# TMS320F28M35x_M3 register map
Vendor: Texas Instruments; Series: C2000 Concerto F28M35x; File version: 0.2.0-generated
CPU: CM3 r2p1, little endian, no MPU, no FPU, 3 interrupt priority bits
Registers are 32-bit, read-write, reset 0x0 unless marked. A register's access mark holds for its fields unless they carry their own. Offsets are from the block's base; [hi:lo] are bit positions; {n}, {i} and the like mark numbered series.

## USB0 — Univeral Serial Bus register offsets
Base 0x40050000
0x00 USB_FADDR 64-bit — USB Device Functional Address
  [12:6] USB_FADDR — Function Address
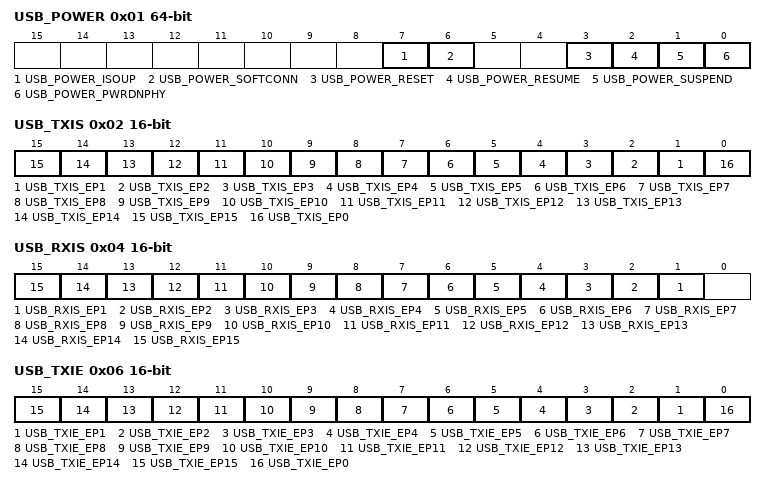
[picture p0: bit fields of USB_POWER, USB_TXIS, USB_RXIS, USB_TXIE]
0x01 USB_POWER 64-bit
  [7] USB_POWER_ISOUP — Isochronous Update
  [6] USB_POWER_SOFTCONN — Soft Connect/Disconnect
  [3] USB_POWER_RESET — RESET Signaling
  [2] USB_POWER_RESUME — RESUME Signaling
  [1] USB_POWER_SUSPEND — SUSPEND Mode
  [0] USB_POWER_PWRDNPHY — Power Down PHY
0x02 USB_TXIS 16-bit — USB Transmit Interrupt Status
  [n] USB_TXIS_EP{n} (n=1..15) — TX Endpoint {n} Interrupt
  [0] USB_TXIS_EP0 — TX and RX Endpoint 0 Interrupt
0x04 USB_RXIS 16-bit — USB Receive Interrupt Status
  [n] USB_RXIS_EP{n} (n=1..15) — RX Endpoint {n} Interrupt
0x06 USB_TXIE 16-bit — USB Transmit Interrupt Enable
  [n] USB_TXIE_EP{n} (n=1..15) — TX Endpoint {n} Interrupt Enable
  [0] USB_TXIE_EP0 — TX and RX Endpoint 0 Interrupt Enable
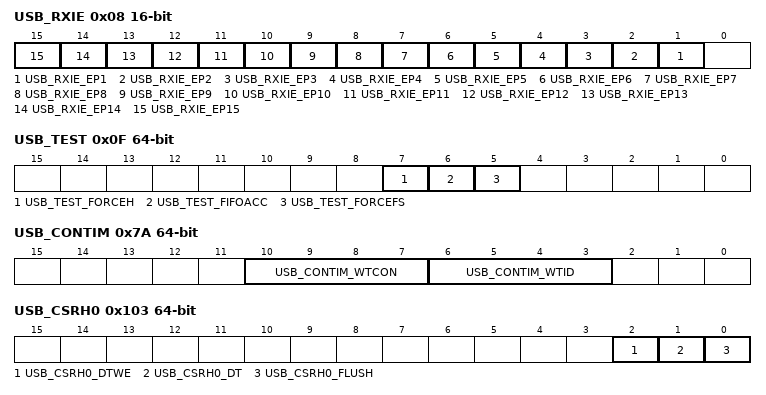
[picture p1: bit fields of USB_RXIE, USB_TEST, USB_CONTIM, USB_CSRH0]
0x08 USB_RXIE 16-bit — USB Receive Interrupt Enable
  [n] USB_RXIE_EP{n} (n=1..15) — RX Endpoint {n} Interrupt Enable
0x0A USB_IS 64-bit — USB General Interrupt Status
  [7] USB_IS_VBUSERR — VBUS Error
  [6] USB_IS_SESREQ — SESSION REQUEST
  [5] USB_IS_DISCON — Session Disconnect
  [4] USB_IS_CONN — Session Connect
  [3] USB_IS_SOF — Start of Frame
  [2] USB_IS_BABBLE — Babble Detected
  [2] USB_IS_RESET — RESET Signaling Detected
  [1] USB_IS_RESUME — RESUME Signaling Detected
  [0] USB_IS_SUSPEND — SUSPEND Signaling Detected
0x0B USB_IE 64-bit — USB Interrupt Enable
  [7] USB_IE_VBUSERR — Enable VBUS Error Interrupt
  [6] USB_IE_SESREQ — Enable Session Request
  [5] USB_IE_DISCON — Enable Disconnect Interrupt
  [4] USB_IE_CONN — Enable Connect Interrupt
  [3] USB_IE_SOF — Enable Start-of-Frame Interrupt
  [2] USB_IE_BABBLE — Enable Babble Interrupt
  [2] USB_IE_RESET — Enable RESET Interrupt
  [1] USB_IE_RESUME — Enable RESUME Interrupt
  [0] USB_IE_SUSPND — Enable SUSPEND Interrupt
0x0C USB_FRAME 16-bit — USB Frame Value
  [15:10] USB_FRAME — Frame Number
0x0E USB_EPIDX 64-bit — USB Endpoint Index
  [6:3] USB_EPIDX_EPIDX — Endpoint Index
0x0F USB_TEST 64-bit — USB Test Mode
  [7] USB_TEST_FORCEH — Force Host Mode
  [6] USB_TEST_FIFOACC — FIFO Access
  [5] USB_TEST_FORCEFS — Force Full-Speed Mode
{0x20+4i} USB_FIFO{i} (i=0..15) — USB FIFO Endpoint {i}
  [31] USB_FIFO{i}_EPDATA — Endpoint Data
0x60 USB_DEVCTL 64-bit — USB Device Control
  [7] USB_DEVCTL_DEV — Device Mode
  [6] USB_DEVCTL_FSDEV — Full-Speed Device Detected
  [5] USB_DEVCTL_LSDEV — Low-Speed Device Detected
  [5:4] USB_DEVCTL_VBUS — VBUS Level
    0=USB_DEVCTL_VBUS_NONE (Below SessionEnd); 8=USB_DEVCTL_VBUS_SEND (Above SessionEnd, below AValid); 16=USB_DEVCTL_VBUS_AVALID (Above AValid, below VBUSValid); 24=USB_DEVCTL_VBUS_VALID (Above VBUSValid)
  [2] USB_DEVCTL_HOST — Host Mode
  [1] USB_DEVCTL_HOSTREQ — Host Request
  [0] USB_DEVCTL_SESSION — Session Start/End
0x62 USB_TXFIFOSZ 64-bit — USB Transmit Dynamic FIFO Sizing
  [4] USB_TXFIFOSZ_DPB — Double Packet Buffer Support
  [6:3] USB_TXFIFOSZ_SIZE — Max Packet Size
    0=8; 1=16; 2=32; 3=64; 4=128; 5=256; 6=512; 7=1024; 8=2048
0x63 USB_RXFIFOSZ 64-bit — USB Receive Dynamic FIFO Sizing
  [4] USB_RXFIFOSZ_DPB — Double Packet Buffer Support
  [6:3] USB_RXFIFOSZ_SIZE — Max Packet Size
    0=8; 1=16; 2=32; 3=64; 4=128; 5=256; 6=512; 7=1024; 8=2048
0x64 USB_TXFIFOADD 16-bit — USB Transmit FIFO Start Address
  [15:8] USB_TXFIFOADD_ADDR — Transmit/Receive Start Address
0x66 USB_RXFIFOADD 16-bit — USB Receive FIFO Start Address
  [15:8] USB_RXFIFOADD_ADDR — Transmit/Receive Start Address
0x7A USB_CONTIM 64-bit — USB Connect Timing
  [10:7] USB_CONTIM_WTCON — Connect Wait
  [6:3] USB_CONTIM_WTID — Wait ID
0x7B USB_VPLEN 64-bit — USB OTG VBUS Pulse Timing
  [14:7] USB_VPLEN_VPLEN — VBUS Pulse Length
0x7D USB_FSEOF 64-bit — USB Full-Speed Last Transaction to End of Frame Timing
  [14:7] USB_FSEOF_FSEOFG — Full-Speed End-of-Frame Gap
0x7E USB_LSEOF 64-bit — USB Low-Speed Last Transaction to End of Frame Timing
  [14:7] USB_LSEOF_LSEOFG — Low-Speed End-of-Frame Gap
{0x80+8i} USB_TXFUNCADDR{i} 64-bit (i=0..15) — USB Transmit Functional Address Endpoint {i}
  [12:6] USB_TXFUNCADDR{i}_ADDR — Device Address
{0x82+8i} USB_TXHUBADDR{i} 64-bit (i=0..15) — USB Transmit Hub Address Endpoint {i}
  [7] USB_TXHUBADDR{i}_MULTTRAN — Multiple Translators
  [12:6] USB_TXHUBADDR{i}_ADDR — Hub Address
{0x83+8i} USB_TXHUBPORT{i} 64-bit (i=0..15) — USB Transmit Hub Port Endpoint {i}
  [12:6] USB_TXHUBPORT{i}_PORT — Hub Port
{0x84+8i} USB_RXFUNCADDR{i} 64-bit (i=1..15) — USB Receive Functional Address Endpoint {i}
  [12:6] USB_RXFUNCADDR{i}_ADDR — Device Address
{0x86+8i} USB_RXHUBADDR{i} 64-bit (i=1..15) — USB Receive Hub Address Endpoint {i}
  [7] USB_RXHUBADDR{i}_MULTTRAN — Multiple Translators
  [12:6] USB_RXHUBADDR{i}_ADDR — Hub Address
{0x87+8i} USB_RXHUBPORT{i} 64-bit (i=1..15) — USB Receive Hub Port Endpoint {i}
  [12:6] USB_RXHUBPORT{i}_PORT — Hub Port
0x102 USB_CSRL0 64-bit — USB Control and Status Endpoint 0 Low
  [7] USB_CSRL0_NAKTO — NAK Timeout
  [7] USB_CSRL0_SETENDC — Setup End Clear
  [6] USB_CSRL0_RXRDYC — RXRDY Clear
  [6] USB_CSRL0_STATUS — STATUS Packet
  [5] USB_CSRL0_REQPKT — Request Packet
  [5] USB_CSRL0_STALL — Send Stall
  [4] USB_CSRL0_ERROR — Error
  [4] USB_CSRL0_SETEND — Setup End
  [3] USB_CSRL0_DATAEND — Data End
  [3] USB_CSRL0_SETUP — Setup Packet
  [2] USB_CSRL0_STALLED — Endpoint Stalled
  [1] USB_CSRL0_TXRDY — Transmit Packet Ready
  [0] USB_CSRL0_RXRDY — Receive Packet Ready
0x103 USB_CSRH0 64-bit — USB Control and Status Endpoint 0 High
  [2] USB_CSRH0_DTWE — Data Toggle Write Enable
  [1] USB_CSRH0_DT — Data Toggle
  [0] USB_CSRH0_FLUSH — Flush FIFO
0x108 USB_COUNT0 64-bit — USB Receive Byte Count Endpoint 0
  [12:6] USB_COUNT0_COUNT — FIFO Count
0x10A USB_TYPE0 64-bit — USB Type Endpoint 0
  [8:7] USB_TYPE0_SPEED — Operating Speed
    128=USB_TYPE0_SPEED_FULL (Full); 192=USB_TYPE0_SPEED_LOW (Low)
0x10B USB_NAKLMT 64-bit — USB NAK Limit
  [8:4] USB_NAKLMT_NAKLMT — EP0 NAK Limit
{0x100+0x10*i} USB_TXMAXP{i} 16-bit (i=1..15) — USB Maximum Transmit Data Endpoint {i}
  [15:10] USB_TXMAXP{i}_MAXLOAD — Maximum Payload
{0x102+0x10*i} USB_TXCSRL{i} 64-bit (i=1..15) — USB Transmit Control and Status Endpoint {i} Low
  [7] USB_TXCSRL{i}_NAKTO — NAK Timeout
  [6] USB_TXCSRL{i}_CLRDT — Clear Data Toggle
  [5] USB_TXCSRL{i}_STALLED — Endpoint Stalled
  [4] USB_TXCSRL{i}_SETUP — Setup Packet
  [4] USB_TXCSRL{i}_STALL — Send STALL
  [3] USB_TXCSRL{i}_FLUSH — Flush FIFO
  [2] USB_TXCSRL{i}_ERROR — Error
  [2] USB_TXCSRL{i}_UNDRN — Underrun
  [1] USB_TXCSRL{i}_FIFONE — FIFO Not Empty
  [0] USB_TXCSRL{i}_TXRDY — Transmit Packet Ready
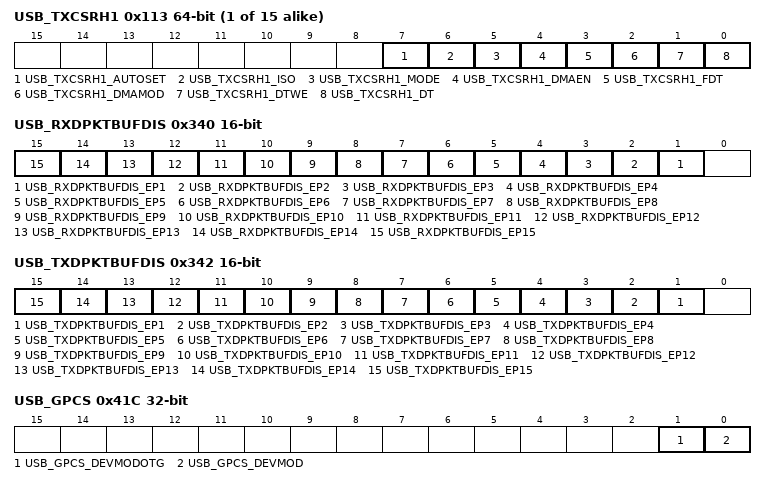
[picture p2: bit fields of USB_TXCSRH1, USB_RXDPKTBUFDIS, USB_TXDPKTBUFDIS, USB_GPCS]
{0x103+0x10*i} USB_TXCSRH{i} 64-bit (i=1..15) — USB Transmit Control and Status Endpoint {i} High
  [7] USB_TXCSRH{i}_AUTOSET — Auto Set
  [6] USB_TXCSRH{i}_ISO — Isochronous Transfers
  [5] USB_TXCSRH{i}_MODE — Mode
  [4] USB_TXCSRH{i}_DMAEN — DMA Request Enable
  [3] USB_TXCSRH{i}_FDT — Force Data Toggle
  [2] USB_TXCSRH{i}_DMAMOD — DMA Request Mode
  [1] USB_TXCSRH{i}_DTWE — Data Toggle Write Enable
  [0] USB_TXCSRH{i}_DT — Data Toggle
{0x104+0x10*i} USB_RXMAXP{i} 16-bit (i=1..15) — USB Maximum Receive Data Endpoint {i}
  [15:10] USB_RXMAXP{i}_MAXLOAD — Maximum Payload
{0x106+0x10*i} USB_RXCSRL{i} 64-bit (i=1..15) — USB Receive Control and Status Endpoint {i} Low
  [7] USB_RXCSRL{i}_CLRDT — Clear Data Toggle
  [6] USB_RXCSRL{i}_STALLED — Endpoint Stalled
  [5] USB_RXCSRL{i}_REQPKT — Request Packet
  [5] USB_RXCSRL{i}_STALL — Send STALL
  [4] USB_RXCSRL{i}_FLUSH — Flush FIFO
  [3] USB_RXCSRL{i}_DATAERR — Data Error
  [3] USB_RXCSRL{i}_NAKTO — NAK Timeout
  [2] USB_RXCSRL{i}_ERROR — Error
  [2] USB_RXCSRL{i}_OVER — Overrun
  [1] USB_RXCSRL{i}_FULL — FIFO Full
  [0] USB_RXCSRL{i}_RXRDY — Receive Packet Ready
{0x107+0x10*i} USB_RXCSRH{i} 64-bit (i=1..15) — USB Receive Control and Status Endpoint {i} High
  [7] USB_RXCSRH{i}_AUTOCL — Auto Clear
  [6] USB_RXCSRH{i}_AUTORQ — Auto Request
  [6] USB_RXCSRH{i}_ISO — Isochronous Transfers
  [5] USB_RXCSRH{i}_DMAEN — DMA Request Enable
  [4] USB_RXCSRH{i}_DISNYET — Disable NYET
  [4] USB_RXCSRH{i}_PIDERR — PID Error
  [3] USB_RXCSRH{i}_DMAMOD — DMA Request Mode
  [2] USB_RXCSRH{i}_DTWE — Data Toggle Write Enable
  [1] USB_RXCSRH{i}_DT — Data Toggle
{0x108+0x10*i} USB_RXCOUNT{i} 16-bit (i=1..15) — USB Receive Byte Count Endpoint {i}
  [15:12] USB_RXCOUNT{i}_COUNT — Receive Packet Count
{0x10A+0x10*i} USB_TXTYPE{i} 64-bit (i=1..15) — USB Host Transmit Configure Type Endpoint {i}
  [8:7] USB_TXTYPE{i}_SPEED — Operating Speed
    0=USB_TXTYPE{i}_SPEED_DFLT (Default); 128=USB_TXTYPE{i}_SPEED_FULL (Full); 192=USB_TXTYPE{i}_SPEED_LOW (Low)
  [6:5] USB_TXTYPE{i}_PROTO — Protocol
    0=USB_TXTYPE{i}_PROTO_CTRL (Control); 16=USB_TXTYPE{i}_PROTO_ISOC (Isochronous); 32=USB_TXTYPE{i}_PROTO_BULK (Bulk); 48=USB_TXTYPE{i}_PROTO_INT (Interrupt)
  [6:3] USB_TXTYPE{i}_TEP — Target Endpoint Number
{0x10B+0x10*i} USB_TXINTERVAL{i} 64-bit (i=1..15) — USB Host Transmit Interval Endpoint {i}
  [14:7] USB_TXINTERVAL{i}_TXPOLL — TX Polling/NAK Limit
{0x10C+0x10*i} USB_RXTYPE{i} 64-bit (i=1..15) — USB Host Configure Receive Type Endpoint {i}
  [8:7] USB_RXTYPE{i}_SPEED — Operating Speed
    0=USB_RXTYPE{i}_SPEED_DFLT (Default); 128=USB_RXTYPE{i}_SPEED_FULL (Full); 192=USB_RXTYPE{i}_SPEED_LOW (Low)
  [6:5] USB_RXTYPE{i}_PROTO — Protocol
    0=USB_RXTYPE{i}_PROTO_CTRL (Control); 16=USB_RXTYPE{i}_PROTO_ISOC (Isochronous); 32=USB_RXTYPE{i}_PROTO_BULK (Bulk); 48=USB_RXTYPE{i}_PROTO_INT (Interrupt)
  [6:3] USB_RXTYPE{i}_TEP — Target Endpoint Number
{0x10D+0x10*i} USB_RXINTERVAL{i} 64-bit (i=1..15) — USB Host Receive Polling Interval Endpoint {i}
  [14:7] USB_RXINTERVAL{i}_TXPOLL — RX Polling/NAK Limit
{0x300+4i} USB_RQPKTCOUNT{i} 16-bit (i=1..3) — USB Request Packet Count in Block Transfer Endpoint {i}
  [15] USB_RQPKTCOUNT{i} — Block Transfer Packet Count
{0x300+4i} USB_RQPKTCOUNT{i} 16-bit (i=4..15) — USB Request Packet Count in Block Transfer Endpoint {i}
  [15] USB_RQPKTCOUNT{i}_COUNT — Block Transfer Packet Count
0x340 USB_RXDPKTBUFDIS 16-bit — USB Receive Double Packet Buffer Disable
  [n] USB_RXDPKTBUFDIS_EP{n} (n=1..15) — EP{n} RX Double-Packet Buffer Disable
0x342 USB_TXDPKTBUFDIS 16-bit — USB Transmit Double Packet Buffer Disable
  [n] USB_TXDPKTBUFDIS_EP{n} (n=1..15) — EP{n} TX Double-Packet Buffer Disable
0x400 USB_EPC — USB External Power Control
  [10:9] USB_EPC_PFLTACT — Power Fault Action
    0=USB_EPC_PFLTACT_UNCHG (Unchanged); 0x100=USB_EPC_PFLTACT_TRIS (Tristate); 0x200=USB_EPC_PFLTACT_LOW (Low); 0x300=USB_EPC_PFLTACT_HIGH (High)
  [6] USB_EPC_PFLTAEN — Power Fault Action Enable
  [5] USB_EPC_PFLTSEN_HIGH — Power Fault Sense
  [4] USB_EPC_PFLTEN — Power Fault Input Enable
  [2] USB_EPC_EPENDE — EPEN Drive Enable
  [2:1] USB_EPC_EPEN — External Power Supply Enable Configuration
    0=USB_EPC_EPEN_LOW (Power Enable Active Low); 1=USB_EPC_EPEN_HIGH (Power Enable Active High); 2=USB_EPC_EPEN_VBLOW (Power Enable High if VBUS Low); 3=USB_EPC_EPEN_VBHIGH (Power Enable High if VBUS High)
0x404 USB_EPCRIS — USB External Power Control Raw Interrupt Status
  [0] USB_EPCRIS_PF — USB Power Fault Interrupt Status
0x408 USB_EPCIM — USB External Power Control Interrupt Mask
  [0] USB_EPCIM_PF — USB Power Fault Interrupt Mask
0x40C USB_EPCISC — USB External Power Control Interrupt Status and Clear
  [0] USB_EPCISC_PF — USB Power Fault Interrupt Status and Clear
0x410 USB_DRRIS — USB Device RESUME Raw Interrupt Status
  [0] USB_DRRIS_RESUME — RESUME Interrupt Status
0x414 USB_DRIM — USB Device RESUME Interrupt Mask
  [0] USB_DRIM_RESUME — RESUME Interrupt Mask
0x418 USB_DRISC — USB Device RESUME Interrupt Status and Clear
  [0] USB_DRISC_RESUME — RESUME Interrupt Status and Clear
0x41C USB_GPCS — USB General-Purpose Control and Status
  [1] USB_GPCS_DEVMODOTG — Enable Device Mode
  [0] USB_GPCS_DEVMOD — Device Mode
0x430 USB_VDC — USB VBUS Droop Control
  [0] USB_VDC_VBDEN — VBUS Droop Enable
0x434 USB_VDCRIS — USB VBUS Droop Control Raw Interrupt Status
  [0] USB_VDCRIS_VD — VBUS Droop Raw Interrupt Status
0x438 USB_VDCIM — USB VBUS Droop Control Interrupt Mask
  [0] USB_VDCIM_VD — VBUS Droop Interrupt Mask
0x43C USB_VDCISC — USB VBUS Droop Control Interrupt Status and Clear
  [0] USB_VDCISC_VD — VBUS Droop Interrupt Status and Clear
0x444 USB_IDVRIS — USB ID Valid Detect Raw Interrupt Status
  [0] USB_IDVRIS_ID — ID Valid Detect Raw Interrupt Status
0x448 USB_IDVIM — USB ID Valid Detect Interrupt Mask
  [0] USB_IDVIM_ID — ID Valid Detect Interrupt Mask
0x44C USB_IDVISC — USB ID Valid Detect Interrupt Status and Clear
  [0] USB_IDVISC_ID — ID Valid Detect Interrupt Status and Clear
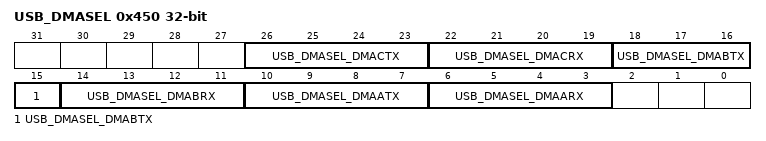
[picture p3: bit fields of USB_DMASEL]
0x450 USB_DMASEL — USB DMA Select
  [26:23] USB_DMASEL_DMACTX — DMA C TX Select
  [22:19] USB_DMASEL_DMACRX — DMA C RX Select
  [18:15] USB_DMASEL_DMABTX — DMA B TX Select
  [14:11] USB_DMASEL_DMABRX — DMA B RX Select
  [10:7] USB_DMASEL_DMAATX — DMA A TX Select
  [6:3] USB_DMASEL_DMAARX — DMA A RX Select
